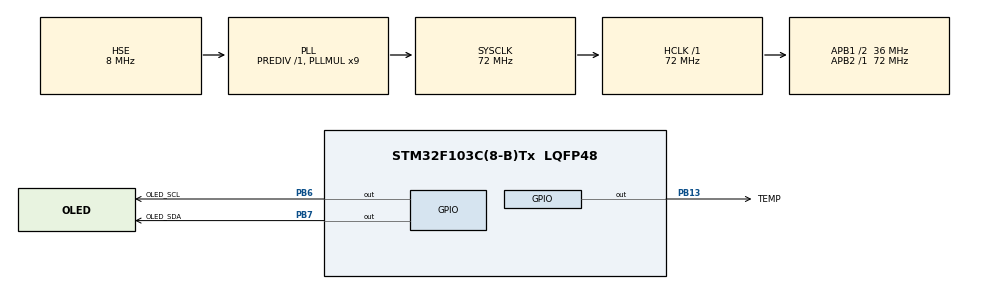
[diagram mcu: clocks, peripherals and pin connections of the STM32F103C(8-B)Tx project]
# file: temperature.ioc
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Mcu.Family=STM32F1
Mcu.Name=STM32F103C(8-B)Tx
Mcu.Package=LQFP48
NVIC.PriorityGroup=NVIC_PRIORITYGROUP_4
PA13.Mode=Serial_Wire
PA13.Signal=SYS_JTMS-SWDIO
PA14.Mode=Serial_Wire
PA14.Signal=SYS_JTCK-SWCLK
PB13.GPIO_Label=TEMP
PB13.GPIO_ModeDefaultOutputPP=GPIO_MODE_OUTPUT_OD
PB13.GPIO_PuPd=GPIO_NOPULL
PB13.Signal=GPIO_Output
PB6.GPIO_Label=OLED_SCL
PB6.GPIO_ModeDefaultOutputPP=GPIO_MODE_OUTPUT_OD
PB6.GPIO_PuPd=GPIO_NOPULL
PB6.Signal=GPIO_Output
PB7.GPIO_Label=OLED_SDA
PB7.GPIO_ModeDefaultOutputPP=GPIO_MODE_OUTPUT_OD
PB7.GPIO_PuPd=GPIO_NOPULL
PB7.Signal=GPIO_Output
PD0-OSC_IN.Mode=HSE-External-Oscillator
PD0-OSC_IN.Signal=RCC_OSC_IN
PD1-OSC_OUT.Mode=HSE-External-Oscillator
PD1-OSC_OUT.Signal=RCC_OSC_OUT
ProjectManager.HeapSize=0x200
ProjectManager.StackSize=0x400
ProjectManager.TargetToolchain=CMake
RCC.AHBFreq_Value=72000000
RCC.APB1CLKDivider=RCC_HCLK_DIV2
RCC.APB1Freq_Value=36000000
RCC.APB1TimFreq_Value=72000000
RCC.APB2Freq_Value=72000000
RCC.APB2TimFreq_Value=72000000
RCC.HCLKFreq_Value=72000000
RCC.PLLMUL=RCC_PLL_MUL9
RCC.PLLSourceVirtual=RCC_PLLSOURCE_HSE
RCC.SYSCLKFreq_VALUE=72000000
RCC.SYSCLKSource=RCC_SYSCLKSOURCE_PLLCLK
RCC.USBFreq_Value=72000000
board=custom

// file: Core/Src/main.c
/* USER CODE BEGIN Header */
/**
  ******************************************************************************
  * @file           : main.c
  * @brief          : Main program body
  ******************************************************************************
  * @attention
  *
  * Copyright (c) 2026 STMicroelectronics.
  * All rights reserved.
  *
  * This software is licensed under terms that can be found in the LICENSE file
  * in the root directory of this software component.
  * If no LICENSE file comes with this software, it is provided AS-IS.
  *
  ******************************************************************************
  */
/* USER CODE END Header */
#include "main.h"
#include "gpio.h"

/* USER CODE BEGIN Includes */
#include <stdio.h>
#include <string.h>
#include "oled.h"
#include "temp.h"
/* USER CODE END Includes */

void SystemClock_Config(void);

int main(void)
{

  /* MCU Configuration--------------------------------------------------------*/

  /* Reset of all peripherals, Initializes the Flash interface and the Systick. */
  HAL_Init();

  /* Configure the system clock */
  SystemClock_Config();

  /* Initialize all configured peripherals */
  MX_GPIO_Init();
  /* USER CODE BEGIN 2 */
  // 初始化 OLED 屏幕
  OLED_Init();
  OLED_Clear();
  OLED_ShowString(1, 1, "Temperature:");

  // 初始化温度传感器（DS18B20）
  Temp_Init();
  HAL_Delay(500);           // 等待传感器稳定
  /* USER CODE END 2 */

  /* Infinite loop */
  /* USER CODE BEGIN WHILE */
  static float last_temp = 25.0f;   // 保存上一次有效温度

  while (1)
  {
      // 读取温度，可能返回 -999（通信失败）
      float temperature = Temp_Read();

      // 有效性检查（DS18B20 测量范围 -55 ~ +125°C）
      if (temperature > -55.0f && temperature < 125.0f)
      {
          last_temp = temperature;   // 更新有效值
      }
      else
      {
          // 读取失败，使用上一次有效值
          temperature = last_temp;
      }

      // 分离整数和小数部分（保留一位小数）
      int int_part = (int)temperature;
      int dec_part = (int)((temperature - int_part) * 10);
      if (dec_part < 0) dec_part = -dec_part;

      char temp_str[16];
      sprintf(temp_str, "%d.%d C", int_part, dec_part);

      // 更新 OLED 显示
      OLED_ShowString(2, 1, "          ");   // 清空第二行
      OLED_ShowString(2, 1, temp_str);

      // 每 2 秒更新一次
      HAL_Delay(2000);
  }
  /* USER CODE END 3 */
}

void SystemClock_Config(void)
{
  RCC_OscInitTypeDef RCC_OscInitStruct = {0};
  RCC_ClkInitTypeDef RCC_ClkInitStruct = {0};

  /** Initializes the RCC Oscillators according to the specified parameters
  * in the RCC_OscInitTypeDef structure.
  */
  RCC_OscInitStruct.OscillatorType = RCC_OSCILLATORTYPE_HSE;
  RCC_OscInitStruct.HSEState = RCC_HSE_ON;
  RCC_OscInitStruct.HSEPredivValue = RCC_HSE_PREDIV_DIV1;
  RCC_OscInitStruct.HSIState = RCC_HSI_ON;
  RCC_OscInitStruct.PLL.PLLState = RCC_PLL_ON;
  RCC_OscInitStruct.PLL.PLLSource = RCC_PLLSOURCE_HSE;
  RCC_OscInitStruct.PLL.PLLMUL = RCC_PLL_MUL9;
  if (HAL_RCC_OscConfig(&RCC_OscInitStruct) != HAL_OK)
  {
    Error_Handler();
  }

  /** Initializes the CPU, AHB and APB buses clocks
  */
  RCC_ClkInitStruct.ClockType = RCC_CLOCKTYPE_HCLK|RCC_CLOCKTYPE_SYSCLK
                              |RCC_CLOCKTYPE_PCLK1|RCC_CLOCKTYPE_PCLK2;
  RCC_ClkInitStruct.SYSCLKSource = RCC_SYSCLKSOURCE_PLLCLK;
  RCC_ClkInitStruct.AHBCLKDivider = RCC_SYSCLK_DIV1;
  RCC_ClkInitStruct.APB1CLKDivider = RCC_HCLK_DIV2;
  RCC_ClkInitStruct.APB2CLKDivider = RCC_HCLK_DIV1;

  if (HAL_RCC_ClockConfig(&RCC_ClkInitStruct, FLASH_LATENCY_2) != HAL_OK)
  {
    Error_Handler();
  }
}

void Error_Handler(void)
{
  __disable_irq();
  while (1)
  {
  }
}
